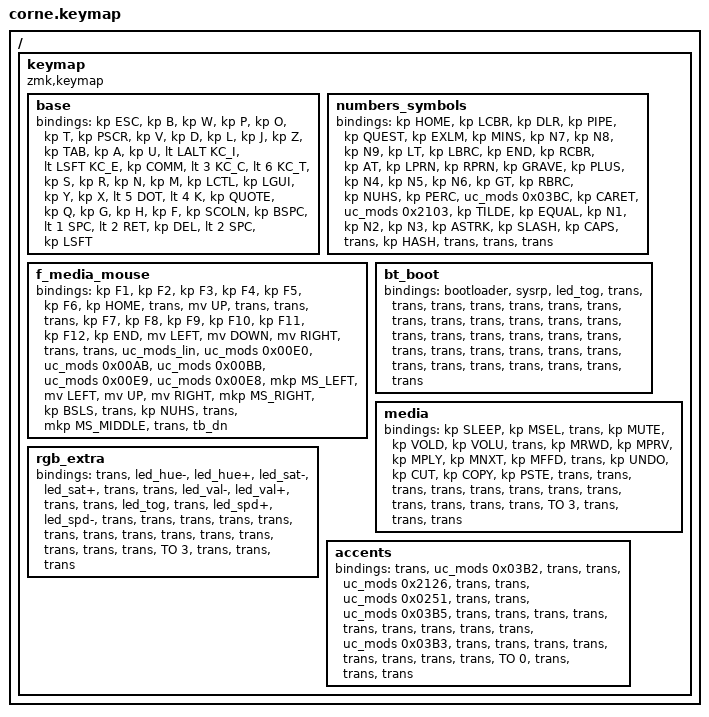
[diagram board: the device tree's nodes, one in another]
#include <behaviors.dtsi>
#include <dt-bindings/zmk/keys.h>
#include <dt-bindings/zmk/bt.h>
#include <dt-bindings/zmk/outputs.h>
#include <dt-bindings/zmk/mods.h>

/ {
    keymap {
        compatible = "zmk,keymap";

        // Layer 0: Base
        base {
            bindings = <
                &kp ESC     &kp B     &kp W     &kp P     &kp O     &kp T
                &kp PSCR    &kp V     &kp D     &kp L     &kp J     &kp Z

                &kp TAB     &kp A     &kp U     &lt LALT KC_I  &lt LSFT KC_E  &kp COMM
                &lt 3 KC_C  &lt 6 KC_T &kp S     &kp R     &kp N     &kp M

                &kp LCTL    &kp LGUI  &kp Y     &kp X     &lt 5 DOT    &lt 4 K
                &kp QUOTE   &kp Q     &kp G     &kp H     &kp F     &kp SCOLN

                &kp BSPC    &lt 1 SPC   &lt 2 RET
                &kp DEL     &lt 2 SPC   &kp LSFT
            >;
        };

        // Layer 1: Numbers/Symbols (TO 1)
        numbers_symbols {
            bindings = <
                &kp HOME    &kp LCBR  &kp DLR   &kp PIPE  &kp QUEST &kp EXLM
                &kp MINS    &kp N7    &kp N8    &kp N9    &kp LT    &kp LBRC

                &kp END     &kp RCBR  &kp AT    &kp LPRN  &kp RPRN  &kp GRAVE
                &kp PLUS    &kp N4    &kp N5    &kp N6    &kp GT    &kp RBRC

                &kp NUHS    &kp PERC  &uc_mods 0x03BC &kp CARET &uc_mods 0x2103 &kp TILDE
                &kp EQUAL   &kp N1    &kp N2    &kp N3    &kp ASTRK &kp SLASH

                &kp CAPS    &trans    &kp HASH
                &trans      &trans    &trans
            >;
        };

        // Layer 2: F-keys/Media/Mouse (TO 2)
        f_media_mouse {
            bindings = <
                &kp F1      &kp F2    &kp F3    &kp F4    &kp F5    &kp F6
                &kp HOME    &trans    &mv UP    &trans    &trans    &trans

                &kp F7      &kp F8    &kp F9    &kp F10   &kp F11   &kp F12
                &kp END     &mv LEFT  &mv DOWN  &mv RIGHT &trans    &trans

                &uc_mods_lin &uc_mods 0x00E0 &uc_mods 0x00AB &uc_mods 0x00BB &uc_mods 0x00E9 &uc_mods 0x00E8
                &mkp MS_LEFT &mv LEFT &mv UP   &mv RIGHT &mkp MS_RIGHT &kp BSLS

                &trans      &kp NUHS  &trans
                &mkp MS_MIDDLE &trans &tb_dn  // Trackball down if wired
            >;
        };

        // Layer 3: BT/Boot/LED (TO 3, simplified no full RGB)
        bt_boot {
            bindings = <
                &bootloader &sysrp    &led_tog  &trans    &trans    &trans  // LED P1.04 toggle
                &trans     &trans    &trans    &trans    &trans    &trans

                &trans     &trans    &trans    &trans    &trans    &trans
                &trans     &trans    &trans    &trans    &trans    &trans

                &trans     &trans    &trans    &trans    &trans    &trans
                &trans     &trans    &trans    &trans    &trans
            >;
        };

        // Layer 4: Media
        media {
            bindings = <
                &kp SLEEP   &kp MSEL  &trans    &kp MUTE  &kp VOLD  &kp VOLU
                &trans     &kp MRWD   &kp MPRV  &kp MPLY  &kp MNXT  &kp MFFD

                &trans     &kp UNDO   &kp CUT   &kp COPY  &kp PSTE  &trans
                &trans     &trans    &trans    &trans    &trans    &trans

                &trans     &trans    &trans    &trans    &trans    &TO 3
                &trans     &trans    &trans
            >;
        };

        // Layer 5: RGB/LED Extra (simplified)
        rgb_extra {
            bindings = <
                &trans     &led_hue- &led_hue+ &led_sat- &led_sat+ &trans
                &trans     &led_val- &led_val+ &trans   &trans    &led_tog

                &trans     &led_spd+ &led_spd- &trans   &trans    &trans
                &trans     &trans    &trans    &trans   &trans    &trans

                &trans     &trans    &trans    &trans   &trans    &TO 3
                &trans     &trans    &trans
            >;
        };

        // Layer 6: Accents/Unicode
        accents {
            bindings = <
                &trans      &uc_mods 0x03B2  &trans    &trans    &uc_mods 0x2126 &trans
                &trans      &uc_mods 0x0251  &trans    &trans    &uc_mods 0x03B5 &trans

                &trans      &trans    &trans    &trans    &trans    &trans
                &trans      &trans    &uc_mods 0x03B3 &trans    &trans    &trans

                &trans      &trans    &trans    &trans    &trans    &TO 0
                &trans      &trans    &trans
            >;
        };
    };
};
